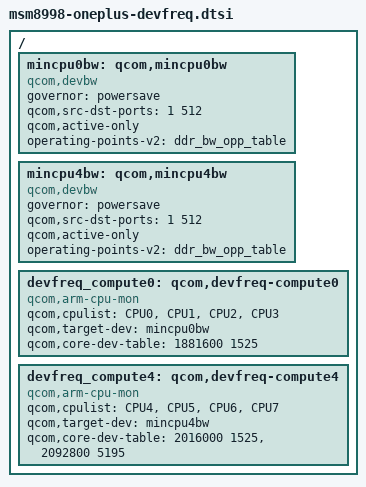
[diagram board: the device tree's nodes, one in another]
/* Copyright (c) 2016-2017, The Linux Foundation. All rights reserved.
 *
 * This program is free software; you can redistribute it and/or modify
 * it under the terms of the GNU General Public License version 2 and
 * only version 2 as published by the Free Software Foundation.
 *
 * This program is distributed in the hope that it will be useful,
 * but WITHOUT ANY WARRANTY; without even the implied warranty of
 * MERCHANTABILITY or FITNESS FOR A PARTICULAR PURPOSE.  See the
 * GNU General Public License for more details.
 */

/ {
	mincpu0bw: qcom,mincpu0bw {
		compatible = "qcom,devbw";
		governor = "powersave";
		qcom,src-dst-ports = <1 512>;
		qcom,active-only;
		operating-points-v2 = <&ddr_bw_opp_table>;
	};

	mincpu4bw: qcom,mincpu4bw {
		compatible = "qcom,devbw";
		governor = "powersave";
		qcom,src-dst-ports = <1 512>;
		qcom,active-only;
		operating-points-v2 = <&ddr_bw_opp_table>;
	};

	devfreq_compute0: qcom,devfreq-compute0 {
		compatible = "qcom,arm-cpu-mon";
		qcom,cpulist = <&CPU0 &CPU1 &CPU2 &CPU3>;
		qcom,target-dev = <&mincpu0bw>;
		qcom,core-dev-table =
			< 1881600 1525 >;
	};

	devfreq_compute4: qcom,devfreq-compute4 {
		compatible = "qcom,arm-cpu-mon";
		qcom,cpulist = <&CPU4 &CPU5 &CPU6 &CPU7>;
		qcom,target-dev = <&mincpu4bw>;
		qcom,core-dev-table =
			< 2016000 1525 >,
			< 2092800 5195 >;
	};
};
